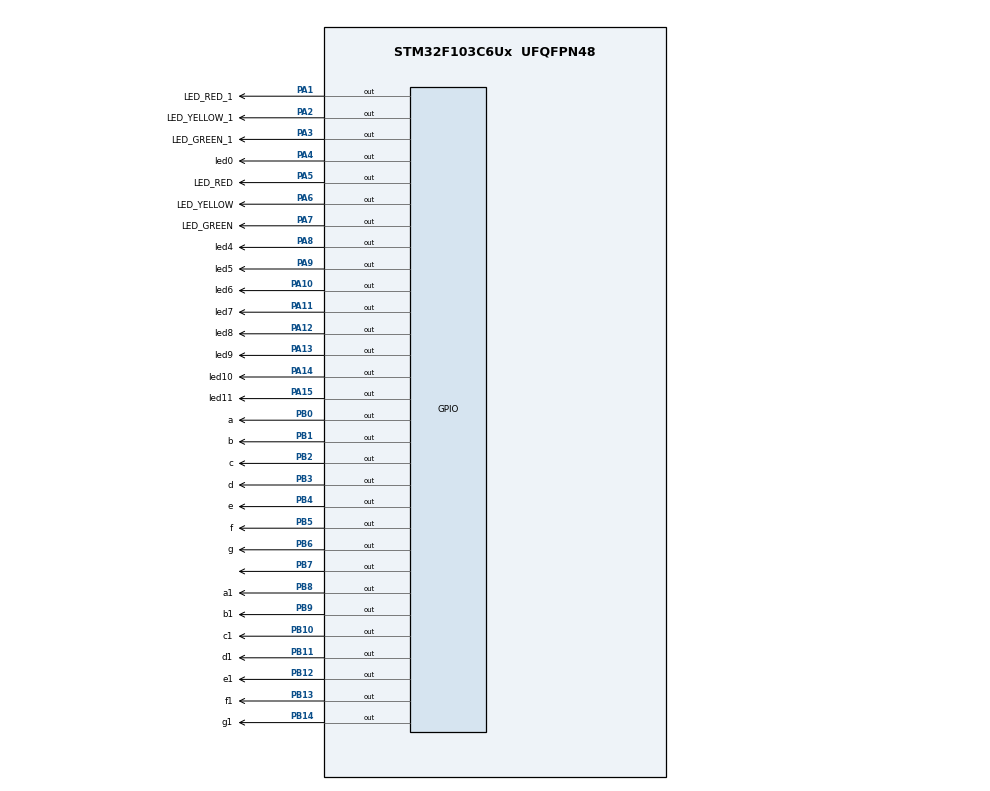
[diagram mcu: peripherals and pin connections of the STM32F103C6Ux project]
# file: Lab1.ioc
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Mcu.Family=STM32F1
Mcu.Name=STM32F103C6Ux
Mcu.Package=UFQFPN48
NVIC.PriorityGroup=NVIC_PRIORITYGROUP_4
PA1.GPIO_Label=LED_RED_1
PA1.Signal=GPIO_Output
PA10.GPIO_Label=led6
PA10.Signal=GPIO_Output
PA11.GPIO_Label=led7
PA11.Signal=GPIO_Output
PA12.GPIO_Label=led8
PA12.Signal=GPIO_Output
PA13.GPIO_Label=led9
PA13.Signal=GPIO_Output
PA14.GPIO_Label=led10
PA14.Signal=GPIO_Output
PA15.GPIO_Label=led11
PA15.Signal=GPIO_Output
PA2.GPIO_Label=LED_YELLOW_1
PA2.Signal=GPIO_Output
PA3.GPIO_Label=LED_GREEN_1
PA3.Signal=GPIO_Output
PA4.GPIO_Label=led0
PA4.Signal=GPIO_Output
PA5.GPIO_Label=LED_RED
PA5.Signal=GPIO_Output
PA6.GPIO_Label=LED_YELLOW
PA6.Signal=GPIO_Output
PA7.GPIO_Label=LED_GREEN
PA7.Signal=GPIO_Output
PA8.GPIO_Label=led4
PA8.Signal=GPIO_Output
PA9.GPIO_Label=led5
PA9.Signal=GPIO_Output
PB0.GPIO_Label=a
PB0.Signal=GPIO_Output
PB1.GPIO_Label=b
PB1.Signal=GPIO_Output
PB10.GPIO_Label=c1
PB10.Signal=GPIO_Output
PB11.GPIO_Label=d1
PB11.Signal=GPIO_Output
PB12.GPIO_Label=e1
PB12.Signal=GPIO_Output
PB13.GPIO_Label=f1
PB13.Signal=GPIO_Output
PB14.GPIO_Label=g1
PB14.Signal=GPIO_Output
PB2.GPIO_Label=c
PB2.Signal=GPIO_Output
PB3.GPIO_Label=d
PB3.Signal=GPIO_Output
PB4.GPIO_Label=e
PB4.Signal=GPIO_Output
PB5.GPIO_Label=f
PB5.Signal=GPIO_Output
PB6.GPIO_Label=g
PB6.Signal=GPIO_Output
PB7.Signal=GPIO_Output
PB8.GPIO_Label=a1
PB8.Signal=GPIO_Output
PB9.GPIO_Label=b1
PB9.Signal=GPIO_Output
ProjectManager.HeapSize=0x200
ProjectManager.StackSize=0x400
ProjectManager.TargetToolchain=STM32CubeIDE
RCC.APB1Freq_Value=8000000
RCC.APB2Freq_Value=8000000
VP_SYS_VS_ND.Mode=No_Debug
board=custom

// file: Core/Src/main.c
/* USER CODE BEGIN Header */
/**
  ******************************************************************************
  * @file           : main.c
  * @brief          : Main program body
  ******************************************************************************
  * @attention
  *
  * <h2><center>&copy; Copyright (c) 2024 STMicroelectronics.
  * All rights reserved.</center></h2>
  *
  * This software component is licensed by ST under BSD 3-Clause license,
  * the "License"; You may not use this file except in compliance with the
  * License. You may obtain a copy of the License at:
  *                        opensource.org/licenses/BSD-3-Clause
  *
  ******************************************************************************
  */
/* USER CODE END Header */
#include "main.h"

/* USER CODE BEGIN Includes */
#include "exercise1.h"
#include "exercise2.h"
#include "exercise3.h"
#include "exercise4.h"
#include "exercise5.h"
#include "exercise6.h"
#include "exercise7.h"
#include "exercise8.h"
#include "exercise9.h"
/* USER CODE END Includes */

void SystemClock_Config(void);
static void MX_GPIO_Init(void);

int main(void)
{

  /* MCU Configuration--------------------------------------------------------*/

  /* Reset of all peripherals, Initializes the Flash interface and the Systick. */
  HAL_Init();

  /* Configure the system clock */
  SystemClock_Config();

  /* Initialize all configured peripherals */
  MX_GPIO_Init();
  /* USER CODE BEGIN 2 */
int count_second = 0;
int count_minute = 0;
int count_hour = 0;
  /* USER CODE END 2 */

  /* Infinite loop */
  while (1)
  {
	  //---------- hien thuc kim giay-----------
	  	  if(count_second == 60)// kim giay chay du 5 vong
	  	  {
	  		  // kiem tra dieu kien kim gio, phut, giay trung nhau
	  		  if((count_second/5 - 1) != (count_minute/5) && (count_second/5 - 1) != count_hour)
	  		  {
	  			  //xoa kim giay, tao hieu ung chuyen dong
	  			  clearNumberOnClock(count_second/5 - 1);
	  		  }
	  		  count_minute ++;// cap nhat minute
	  		  count_second = 0;// reset second ve 0
	  	  }

	  	  // kiem tra dieu kien kim gio, phut, giay trung nhau
	  	  if((count_second/5 - 1) != (count_minute/5) && (count_second/5 - 1) != count_hour)
	  	  {
	  		  clearNumberOnClock(count_second/5 - 1);
	  	  }
	  	  // hien thi kim giay
	  	  setNumberOnClock(count_second/5);
	  	  count_second ++;

	  	  //--------- hien thuc kim phut----------
	  	  if(count_minute == 60)//kim phut chay du 1 vong
	  	  {
	  		  // kiem tra dieu kien kim gio, phut, giay trung nhau
	  		  if((count_minute/5 -1) != (count_second/5) && (count_minute/5 -1) != count_hour)
	  		  {
	  			  //xoa kim phut, tao hieu ung chuyen dong
	  			  clearNumberOnClock(count_minute/5 -1);
	  		  }
	  		  count_hour ++;// cap nhat kim gio
	  		  count_minute = 0;// reset kim phut ve 0
	  	  }

	  	  // kiem tra dieu kien kim gio, phut, giay trung nhau
	  	  if((count_minute/5 -1) != (count_second/5) && (count_minute/5 -1) != count_hour)
	  	  {
	  		  //xoa kim phut, tao hieu ung chuyen dong
	  		  clearNumberOnClock(count_minute/5 -1);
	  	  }
	  	  // hien thi kim phut
	  	  setNumberOnClock(count_minute/5);

	  	  // ------------hien thuc kim gio------------
	  	  if(count_hour == 12)// kim gio quay duoc 1 vong
	  	  {
	  		  // kiem tra dieu kien kim gio, phut, giay trung nhau
	  		  if((count_hour -1) != (count_minute/5) && (count_hour -1) != (count_second/5))
	  		  {
	  			  //xoa kim gio, tao hieu ung chuyen dong
	  			  clearNumberOnClock(count_hour -1);
	  		  }
	  		  count_hour = 0;// reset kim phut ve 0
	  	  }
	  	  // kiem tra dieu kien kim gio, phut, giay trung nhau
	  	  if((count_hour -1) != (count_minute/5) && (count_hour -1) != (count_second/5))
	  	  {
	  		  //xoa kim gio, tao hieu ung chuyen dong
	  		  clearNumberOnClock(count_hour -1);
	  	  }
	  	  // hien thi kim gio
	  	  setNumberOnClock(count_hour);
HAL_Delay(10);
  }
}

void SystemClock_Config(void)
{
  RCC_OscInitTypeDef RCC_OscInitStruct = {0};
  RCC_ClkInitTypeDef RCC_ClkInitStruct = {0};

  /** Initializes the RCC Oscillators according to the specified parameters
  * in the RCC_OscInitTypeDef structure.
  */
  RCC_OscInitStruct.OscillatorType = RCC_OSCILLATORTYPE_HSI;
  RCC_OscInitStruct.HSIState = RCC_HSI_ON;
  RCC_OscInitStruct.HSICalibrationValue = RCC_HSICALIBRATION_DEFAULT;
  RCC_OscInitStruct.PLL.PLLState = RCC_PLL_NONE;
  if (HAL_RCC_OscConfig(&RCC_OscInitStruct) != HAL_OK)
  {
    Error_Handler();
  }
  /** Initializes the CPU, AHB and APB buses clocks
  */
  RCC_ClkInitStruct.ClockType = RCC_CLOCKTYPE_HCLK|RCC_CLOCKTYPE_SYSCLK
                              |RCC_CLOCKTYPE_PCLK1|RCC_CLOCKTYPE_PCLK2;
  RCC_ClkInitStruct.SYSCLKSource = RCC_SYSCLKSOURCE_HSI;
  RCC_ClkInitStruct.AHBCLKDivider = RCC_SYSCLK_DIV1;
  RCC_ClkInitStruct.APB1CLKDivider = RCC_HCLK_DIV1;
  RCC_ClkInitStruct.APB2CLKDivider = RCC_HCLK_DIV1;

  if (HAL_RCC_ClockConfig(&RCC_ClkInitStruct, FLASH_LATENCY_0) != HAL_OK)
  {
    Error_Handler();
  }
}

static void MX_GPIO_Init(void)
{
  GPIO_InitTypeDef GPIO_InitStruct = {0};

  /* GPIO Ports Clock Enable */
  __HAL_RCC_GPIOA_CLK_ENABLE();
  __HAL_RCC_GPIOB_CLK_ENABLE();

  /*Configure GPIO pin Output Level */
  HAL_GPIO_WritePin(GPIOA, LED_RED_1_Pin|LED_YELLOW_1_Pin|LED_GREEN_1_Pin|led0_Pin
                          |LED_RED_Pin|LED_YELLOW_Pin|LED_GREEN_Pin|led4_Pin
                          |led5_Pin|led6_Pin|led7_Pin|led8_Pin
                          |led9_Pin|led10_Pin|led11_Pin, GPIO_PIN_RESET);

  /*Configure GPIO pin Output Level */
  HAL_GPIO_WritePin(GPIOB, a_Pin|b_Pin|c_Pin|c1_Pin
                          |d1_Pin|e1_Pin|f1_Pin|g1_Pin
                          |d_Pin|e_Pin|f_Pin|g_Pin
                          |GPIO_PIN_7|a1_Pin|b1_Pin, GPIO_PIN_RESET);

  /*Configure GPIO pins : LED_RED_1_Pin LED_YELLOW_1_Pin LED_GREEN_1_Pin led0_Pin
                           LED_RED_Pin LED_YELLOW_Pin LED_GREEN_Pin led4_Pin
                           led5_Pin led6_Pin led7_Pin led8_Pin
                           led9_Pin led10_Pin led11_Pin */
  GPIO_InitStruct.Pin = LED_RED_1_Pin|LED_YELLOW_1_Pin|LED_GREEN_1_Pin|led0_Pin
                          |LED_RED_Pin|LED_YELLOW_Pin|LED_GREEN_Pin|led4_Pin
                          |led5_Pin|led6_Pin|led7_Pin|led8_Pin
                          |led9_Pin|led10_Pin|led11_Pin;
  GPIO_InitStruct.Mode = GPIO_MODE_OUTPUT_PP;
  GPIO_InitStruct.Pull = GPIO_NOPULL;
  GPIO_InitStruct.Speed = GPIO_SPEED_FREQ_LOW;
  HAL_GPIO_Init(GPIOA, &GPIO_InitStruct);

  /*Configure GPIO pins : a_Pin b_Pin c_Pin c1_Pin
                           d1_Pin e1_Pin f1_Pin g1_Pin
                           d_Pin e_Pin f_Pin g_Pin
                           PB7 a1_Pin b1_Pin */
  GPIO_InitStruct.Pin = a_Pin|b_Pin|c_Pin|c1_Pin
                          |d1_Pin|e1_Pin|f1_Pin|g1_Pin
                          |d_Pin|e_Pin|f_Pin|g_Pin
                          |GPIO_PIN_7|a1_Pin|b1_Pin;
  GPIO_InitStruct.Mode = GPIO_MODE_OUTPUT_PP;
  GPIO_InitStruct.Pull = GPIO_NOPULL;
  GPIO_InitStruct.Speed = GPIO_SPEED_FREQ_LOW;
  HAL_GPIO_Init(GPIOB, &GPIO_InitStruct);

}

void Error_Handler(void)
{
  __disable_irq();
  while (1)
  {
  }
}

/************************ (C) COPYRIGHT STMicroelectronics *****END OF FILE****/
